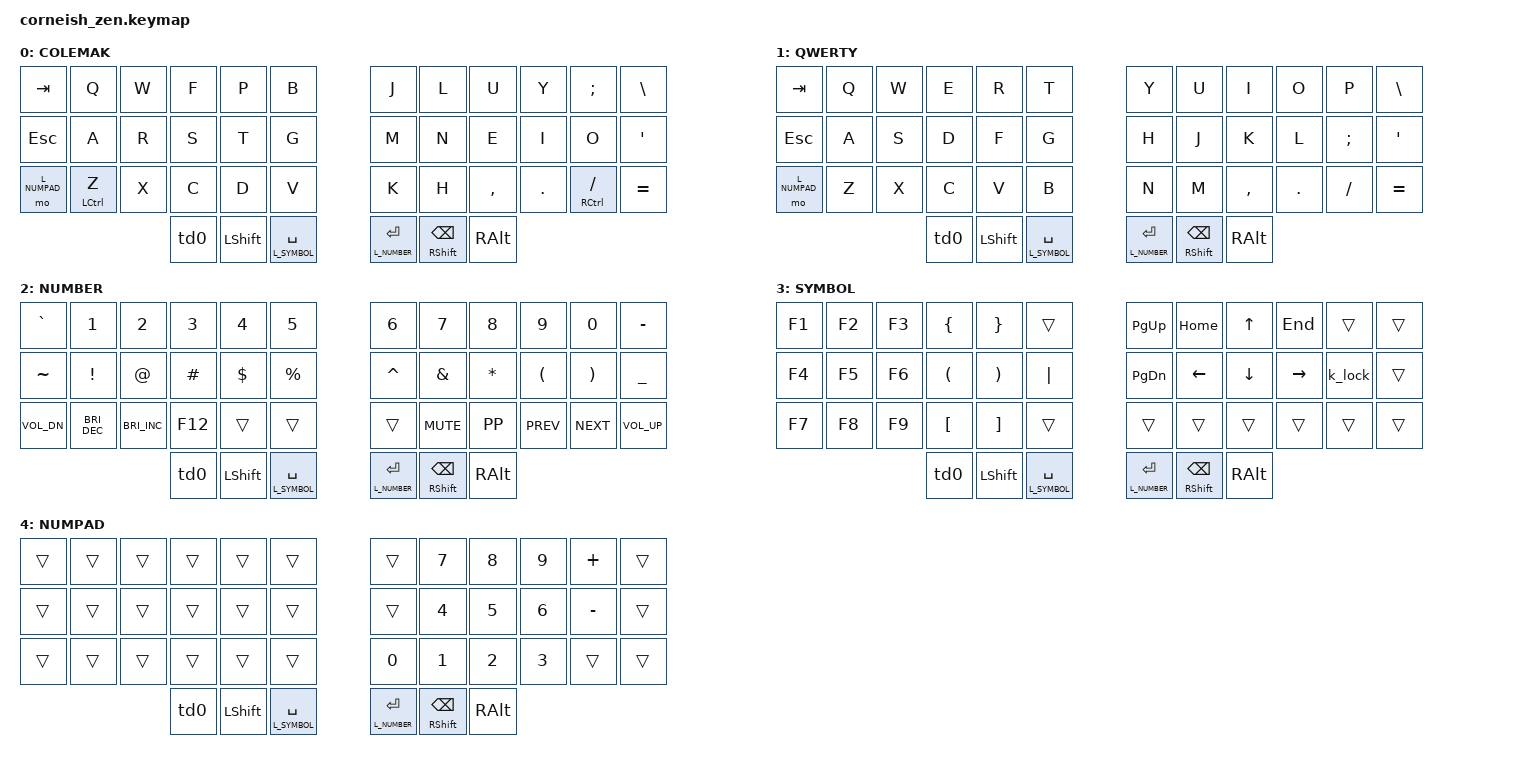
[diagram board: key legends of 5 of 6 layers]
#include <behaviors.dtsi>
#include <dt-bindings/zmk/keys.h>
#include <dt-bindings/zmk/bt.h>

#define L_DEFAULT 0 // COLEMAK is the default layout
#define L_QWERTY 1
#define L_NUMBER 2
#define L_SYMBOL 3
#define L_NUMPAD 4
#define L_ADJUST 5

/ {
  chosen {
    zmk,matrix_transform = &default_transform;
  };
};

/ {
        macros {
          gui_and_space: gui_and_space {
            label = "ZM_gui_and_space";
            compatible = "zmk,behavior-macro";
            #binding-cells = <0>;
            wait-ms = <1>;
            bindings
                = <&macro_press &kp LGUI>
                , <&macro_tap &kp SPACE>
                , <&macro_release &kp LGUI>
                ;
          };

          k_lock: k_lock {
           label = "ZM_k_lock";
           compatible = "zmk,behavior-macro";
           #binding-cells = <0>;
           wait-ms = <1>;
           bindings
                = <&macro_press &kp LGUI>
                , <&macro_press &kp LCTRL>
                , <&macro_tap   &kp Q>
                , <&macro_release &kp LCTRL>
                , <&macro_release &kp LGUI>
                ;
           };
        };

        behaviors {
          td0: tap_dance_0 {
            compatible = "zmk,behavior-tap-dance";
            label = "TAP_DANCE_0";
            #binding-cells = <0>;
            tapping-term-ms = <200>;
            bindings = <&kp LGUI>, <&gui_and_space>;
          };           
        };
                
        conditional_layers {
         compatible = "zmk,conditional-layers";                        
         tri_layer {
           if-layers = <L_NUMBER L_SYMBOL>;
           then-layer = <L_ADJUST>;                        
         };
        };

        keymap {
                compatible = "zmk,keymap";

                default_layer {
                        label = "COLEMAK";
// -----------------------------------------------------------------------------------------
// | TAB  |  Q  |  W  |  F  |  P  |  B  |   |  J  |  L   |  U  |  Y  |  ;  |  \   |
// | ESC  |  A  |  R  |  S  |  T  |  G  |   |  M  |  N   |  E  |  I  |  O  |  '   |
// | L_NUMPAD |  Z  |  X  |  C  |  D  |  V  |   |  K  |  H   |  ,  |  .  |  /  |  =   |
//                    | GUI | SHFT| SPC/NUMBER |   | ENT/SYMBOL | SHFT/BSPC | BKSP|
                        bindings = <
   &kp TAB   &kp Q &kp W &kp F &kp P &kp B   &kp J &kp L  &kp U  &kp Y  &kp SEMI    &kp BSLH
   &kp ESC   &kp A &kp R &kp S &kp T &kp G   &kp M &kp N  &kp E  &kp I  &kp O &kp SQT
   &mo L_NUMPAD &mt LCTRL Z &kp X &kp C &kp D  &kp V  &kp K &kp H &kp COMMA &kp DOT &mt RCTRL FSLH &kp EQUAL
              &td0 &kp LSHIFT &lt  L_SYMBOL SPACE   &lt L_NUMBER  RET &mt RSHIFT BSPC &kp RALT
                        >;
                };
				
				
                qwerty_layer {
                        label = "QWERTY";
// -----------------------------------------------------------------------------------------
// |  TAB |  Q  |  W  |  E  |  R  |  T  |   |  Y  |  U   |  I  |  O  |  P  | \        |
// | ESC  |  A  |  S  |  D  |  F  |  G  |   |  H  |  J   |  K  |  L  |  ;  |  '       |
// | L_NUMPAD |  Z  |  X  |  C  |  V  |  B  |   |  N  |  M   |  ,  |  .  |  /  |  =   |
//                    | GUI | LWR | SPC |   | ENT | RSE  | ALT |
                        bindings = <
   &kp TAB   &kp Q &kp W &kp E &kp R &kp T   &kp Y &kp U  &kp I     &kp O   &kp P    &kp BSLH
   &kp ESC &kp A &kp S &kp D &kp F &kp G   &kp H &kp J  &kp K     &kp L   &kp SEMI &kp SQT
   &mo L_NUMPAD &kp Z &kp X &kp C &kp V &kp B   &kp N &kp M  &kp COMMA &kp DOT &kp FSLH &kp EQUAL
              &td0 &kp LSHIFT &lt L_SYMBOL  SPACE    &lt L_NUMBER RET &mt RSHIFT BSPC &kp RALT
                        >;
                };
				
                number_layer {
                        label = "NUMBER";
// -----------------------------------------------------------------------------------------
// |  `   |  1  |  2  |  3  |  4  |  5  |   |  6  |  7  |  8  |  9  |  0  |  -   |
// |  ~   |  !  |  @  |  #  |  $  |  %  |   |  ^  |  &  |  *  |  (  |  )  |  _   |
// | XXXX |     |     |     |     |     |   |     |     |     |     |     |      |
//                    | GUI |     | SPC |   | ENT |     | ALT |
                        bindings = <
   &kp GRAVE    &kp N1       &kp N2       &kp N3       &kp N4       &kp N5         &kp N6   &kp N7   &kp N8 &kp N9    &kp N0 &kp MINUS
   &kp TILDE    &kp EXCLAMATION &kp AT_SIGN &kp HASH &kp DOLLAR &kp PERCENT &kp CARET &kp AMPS &kp STAR &kp LPAR &kp RPAR &kp UNDERSCORE
   &kp C_VOL_DN  &kp C_BRI_DEC &kp C_BRI_INC &kp F12  &trans &trans &trans   &kp K_MUTE  &kp K_PP &kp K_PREV &kp K_NEXT &kp C_VOL_UP
              &td0 &kp LSHIFT &lt L_SYMBOL SPACE  &lt L_NUMBER RET &mt RSHIFT BSPC &kp RALT
                        >;
                };

                symbol_layer {
                        label = "SYMBOL";
// -----------------------------------------------------------------------------------------
// |  F1 |  F2  |  F3  |  {  |  }  |     |   |  pg_up  |  home  |  up  |  end  |         |  |
// | F4 |  F5  | F6  |  (  |   )  |  "|" |   |  pg_dn |  left  |  down  |  right  |  K_LOCK  |     |
// | F7 | F8 |  F9 |  [  |  ]  |    |   |    |    |  |  |    |     |
//                    | GUI |     | SPC |   | ENT |     | ALT |
                        bindings = <
   &kp F1 &kp F2 &kp F3 &kp LBRC &kp RBRC &trans   &kp PG_UP &kp HOME  &kp UP   &kp END &trans &trans
   &kp F4 &kp F5 &kp F6 &kp LPAR &kp RPAR &kp PIPE &kp PG_DN &kp LEFT  &kp DOWN &kp RIGHT &k_lock &trans
   &kp F7 &kp F8 &kp F9 &kp LBKT &kp RBKT &trans   &trans    &trans    &trans   &trans    &trans &trans
              &td0 &kp LSHIFT &lt L_SYMBOL SPACE  &lt L_NUMBER  RET &mt RSHIFT BSPC &kp RALT
                        >;
                };
                                               
                numpad_layer {
                        label = "NUMPAD";
// -----------------------------------------------------------------------------------------
// |  TAB |  Q  |  W  |  E  |  R  |  T  |   |  Y  |  7   |  8  |  9  |  +  | BKSP |
// | ESC  |  A  |  S  |  D  |  F  |  G  |   |  H  |  4   |  5  |  6  |  -  |  '   |
// | L_NUMPAD |  Z  |  X  |  C  |  V  |  B  | 0  |  1  |  2   |  3  |  /  |  =   |
//                    | GUI | LWR | SPC |   | ENT | RSE  | ALT |
                        bindings = <
   &trans &trans &trans &trans &trans &trans &trans &kp N7  &kp N8  &kp N9   &kp PLUS  &trans
   &trans &trans &trans &trans &trans &trans &trans &kp N4  &kp N5  &kp N6   &kp MINUS &trans
   &trans &trans &trans &trans &trans &trans &kp N0 &kp N1  &kp N2  &kp N3   &trans    &trans
              &td0 &kp LSHIFT &lt L_SYMBOL SPACE  &lt L_NUMBER RET &mt RSHIFT BSPC &kp RALT
                        >;
                };
                
				
                adjust_layer {
                        label = "ADJUST";
// -----------------------------------------------------------------------------------------
// | TAB       |  XXX  |  XXX    |  XXX  |  XXX  |  XXX   |   |  XXX  |  XXX   |  XXX  |  XXX     |  COLEMAK  | QWERTY |
// | BTCLR     |  BT1  |  BT2    |  BT3  |  BT4  |  BT5   |   |  XXX  |  XXX   |  XXX  |  XXX     |  XXX      |  XXX   |
// | SHFT      |  XXX  |  XXX    |  XXX  |  XXX  |  XXX   |   |  XXX  |  XXX   |  XXX  |  XXX     |  XXX      |  XXX   |
//                    | GUI | LWR | SPC |   | ENT | RSE  | ALT |
                        bindings = <
   &none       &none   &none     &none   &none   &none        &none    &none   &none      &none   &to L_DEFAULT &to L_QWERTY
   &bt BT_CLR  &bt BT_SEL 0 &bt BT_SEL 1 &bt BT_SEL 2 &bt BT_SEL 3 &bt BT_SEL 4 &bt BT_SEL 5 &none &none &none &none &none &none
   &none       &none   &none     &none   &none   &none        &none    &none   &none      &none   &none         &none
              &td0 &kp LSHIFT &lt L_SYMBOL SPACE   &lt  L_NUMBER RET &mt RSHIFT BSPC &kp RALT 
                        >;
                };
		};
};
/*
layout:
  ortho_layout:
    split: true
    rows: 3
    columns: 6
    thumbs: 3
layers:
  COLEMAK:
    - ["Tab", "Q", "W", "F", "P", "B", "J", "L", "U", "Y", ";", "\\"]
    - ["ESC", "A", "R", "S", "T", "G", "M", "N", "E", "I", "O", "'"]
    - ["L_NUMPAD", "Z", "X", "C", "D", "V", "K", "H", ",", ".", "/", "="]
    - ["LGui", "SHFT", "SPC/SYM ", "ENT/\nNUM", "SHFT/\nBSPC", "Bspace"]
  QWERTY:
    - ["Tab", "Q", "W", "E", "R", "T", "Y", "U", "I", "O", "P", "\\"]
    - ["ESC", "A", "S", "D", "F", "G", "H", "J", "K", "L", ";", "'" ]
    - ["L_NUMPAD", "Z", "X", "C", "V", "B", "N", "M", ",", ".", "/", "="]
    - ["LGui", "LWR", "SPC", "ENT", "RSE", "ALT"]
  NUMBER:
    - ["`", "1", "2", "3", "4", "5", "6", "7", "8", "9", "0", "-"]
    - ["~", "!", "@", "#", "$", "%", "^", "&", "*", "(", ")", "_"]
    - [null, null, null, null, null, null, null, null, null, null, null, null]
    - ["LGui", null, "SPC", "ENT", null,  "ALT"]
  SYMBOL:
    - ["F1", "F2", "F3", "{", "}", null, "pg_up", "home", "up", "end", null, null]
    - ["F2", "F5", "F6", "(", ")", "|", "pg_dn", "left", "down", "right", "K_LOCK", null]
    - ["F7", "F8", "F9", "[", "]", null, null, null, null, null, null, null]
    - ["LGui", null, "SPC", "ENT", null, "ALT"]
  NUMPAD:
    - ["Tab", "Q", "W", "E", "R", "T", "Y", "7", "8", "9", "+", "Bspace"]
    - ["ESC", "A", "S", "D", "F", "G", "H", "4", "5", "6", "-", "'"]
    - ["L_NUMPAD", "Z", "X", "C", "V", "B", "0", "1", "2", "3", "/", "="]
    - ["LGui", "LWR", "SPC", "ENT", "RSE", "ALT"]
  ADJUST:
    - ["Tab", null, null, null, null, null, null, null, null, null, "COLEMAK", "QWERTY"]
    - ["BT CLR", "BT 1", "BT 2", "BT 3", "BT 4", "BT 5", null, null, null, null, null, null]
    - ["SHFT", null, null, null, null, null, null, null, null, null, null, null]
    - ["LGui", "LWR", "SPC", "ENT", "RSE", "ALT"]

for:
https://caksoylar-keymap-drawer-streamlitapp-2a0rau.streamlit.app
https://github.com/caksoylar/keymap-drawer
*/
